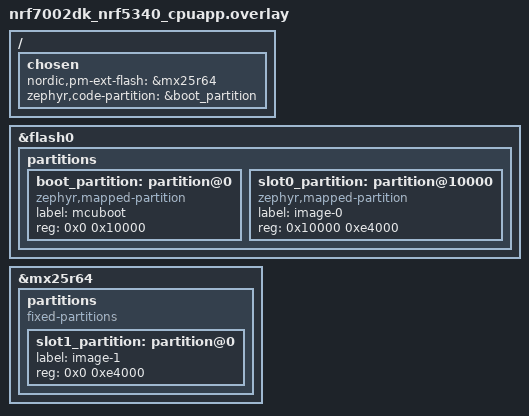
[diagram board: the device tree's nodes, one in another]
/*
 * Copyright (c) 2023 Nordic Semiconductor ASA
 *
 * SPDX-License-Identifier: LicenseRef-Nordic-5-Clause
 */

/ {
	/* Configure the partition manager to use the mx25r64 external flash memory. */
	chosen {
		nordic,pm-ext-flash = &mx25r64;
		zephyr,code-partition = &boot_partition;
	};
};

/delete-node/ &boot_partition;
/delete-node/ &slot0_partition;
/delete-node/ &slot1_partition;

&flash0 {
	partitions {
		boot_partition: partition@0 {
			compatible = "zephyr,mapped-partition";
			label = "mcuboot";
			reg = <0x0 0x10000>;
		};

		/* Keep MCUboot primary slot aligned with the application devicetree layout. */
		slot0_partition: partition@10000 {
			compatible = "zephyr,mapped-partition";
			label = "image-0";
			reg = <0x10000 0xe4000>;
		};
	};
};

&mx25r64 {
	status = "okay";

	partitions {
		compatible = "fixed-partitions";
		#address-cells = <1>;
		#size-cells = <1>;

		slot1_partition: partition@0 {
			label = "image-1";
			reg = <0x0 0xe4000>;
		};
	};
};
